# STM32F401CBU3 register map
File version: 1.0
STM32F401CBU3,STM32F401CBU6,STM32F401CBU7,STM32F401CBY6,STM32F401CCF6,STM32F401CCF7,STM32F401CCU6,STM32F401CCU7,STM32F401CCY6,STM32F401CCY7,STM32F401CDU6,STM32F401CDY6,STM32F401CEU6,STM32F401CEY6,STM32F401RBT6,STM32F401RCT6,STM32F401RCT7,STM32F401RDT6,STM32F401RDT7,STM32F401RET6,STM32F401RET7,STM32F401VBH3,STM32F401VBH6,STM32F401VBH7,STM32F401VBT3,STM32F401VBT6,STM32F401VBT7,STM32F401VCH6,STM32F401VCH7,STM32F401VCT6,STM32F401VCT7,STM32F401VDH6,STM32F401VDT6,STM32F401VEH6,STM32F401VEH7,STM32F401VET6,STM32F401VET7
Registers are 32-bit, access not given, reset 0x0 unless marked. A register's access mark holds for its fields unless they carry their own. Offsets are from the block's base; lines under a group give offsets from that group; [hi:lo] are bit positions; {n}, {i} and the like mark numbered series; 'fields as' and 'values as' point back to an identical list; <NAME> marks a mode.

## Memory map
0x40000000 TIM2
0x40000400 TIM3
0x40000800 TIM4
0x40000C00 TIM5
0x40002800 BKP
0x40002800 RTC
0x40002C00 WWDG
0x40003000 IWDG
0x40003800 SPI2
0x40003C00 SPI3
0x40004400 USART2
0x40005400 I2C1
0x40005800 I2C2
0x40005C00 I2C3
0x40007000 PWR
0x40010000 TIM1
0x40011000 USART1
0x40011400 USART6
0x40012000 ADC1
0x40012C00 SDIO
0x40013000 SPI1
0x40013400 SPI4
0x40013800 SYSCFG
0x40013C00 EXTI
0x40014000 TIM9
0x40014400 TIM10
0x40014800 TIM11
0x40020000 GPIOA
0x40020400 GPIOB
0x40020800 GPIOC
0x40020C00 GPIOD
0x40021000 GPIOE
0x40021C00 GPIOH
0x40023000 CRC
0x40023800 RCC
0x40023C00 FLASH
0x40026000 DMA1
0x40026400 DMA2
0x50000000 USB_OTG_FS

## TIM2
Base 0x40000000
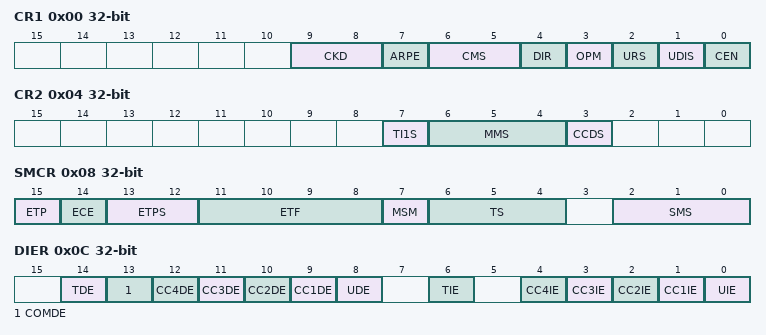
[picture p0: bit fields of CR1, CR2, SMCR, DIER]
0x00 CR1
  [9:8] CKD, [7] ARPE, [6:5] CMS, [4] DIR, [3] OPM, [2] URS, [1] UDIS, [0] CEN
0x04 CR2
  [7] TI1S, [6:4] MMS, [3] CCDS
0x08 SMCR
  [15] ETP, [14] ECE, [13:12] ETPS, [11:8] ETF, [7] MSM, [6:4] TS, [2:0] SMS
0x0C DIER
  [14] TDE, [13] COMDE, [n+8] CC{n}DE (n=1..4), [8] UDE, [6] TIE, [n] CC{n}IE (n=1..4), [0] UIE
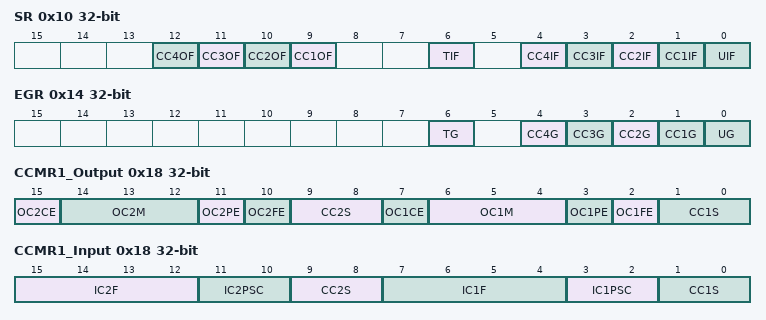
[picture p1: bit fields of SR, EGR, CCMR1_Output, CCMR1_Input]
0x10 SR
  [n+8] CC{n}OF (n=1..4), [6] TIF, [n] CC{n}IF (n=1..4), [0] UIF
0x14 EGR
  [6] TG, [n] CC{n}G (n=1..4), [0] UG
0x18 CCMR1_Output
  [15] OC2CE, [14:12] OC2M, [11] OC2PE, [10] OC2FE, [9:8] CC2S, [7] OC1CE, [6:4] OC1M, [3] OC1PE, [2] OC1FE, [1:0] CC1S
0x18 CCMR1_Input
  [15:12] IC2F, [11:10] IC2PSC, [9:8] CC2S, [7:4] IC1F, [3:2] IC1PSC, [1:0] CC1S
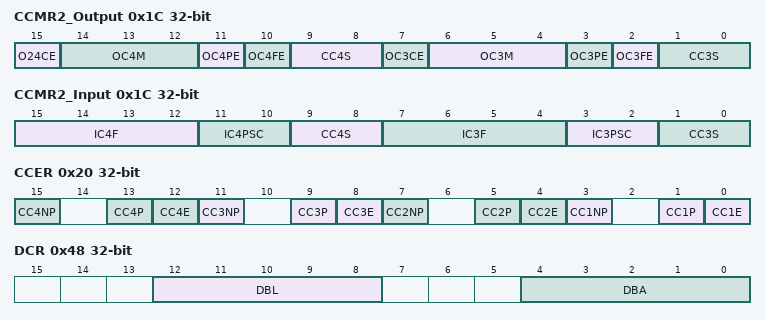
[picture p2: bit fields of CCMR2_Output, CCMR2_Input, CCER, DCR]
0x1C CCMR2_Output
  [15] O24CE, [14:12] OC4M, [11] OC4PE, [10] OC4FE, [9:8] CC4S, [7] OC3CE, [6:4] OC3M, [3] OC3PE, [2] OC3FE, [1:0] CC3S
0x1C CCMR2_Input
  [15:12] IC4F, [11:10] IC4PSC, [9:8] CC4S, [7:4] IC3F, [3:2] IC3PSC, [1:0] CC3S
0x20 CCER
  [4n-1] CC{n}NP (n=1..4), [4n-3] CC{n}P (n=1..4), [4n-4] CC{n}E (n=1..4)
0x24 CNT
0x28 PSC
  [15:0] PSC
0x2C ARR
{0x30+4i} CCR{i} (i=1..4)
0x48 DCR
  [12:8] DBL, [4:0] DBA
0x4C DMAR
  [15:0] DMAB
0x50 OR
  [11:10] ITR1_RMP

## TIM3
Base 0x40000400
Registers as TIM2, without OR.

## TIM4
Base 0x40000800
Registers as TIM2, without OR.

## TIM5
Base 0x40000C00
Registers as TIM2; these are added or differ:
0x50 OR
  [7:6] IT4_RMP

## BKP
Base 0x40002800
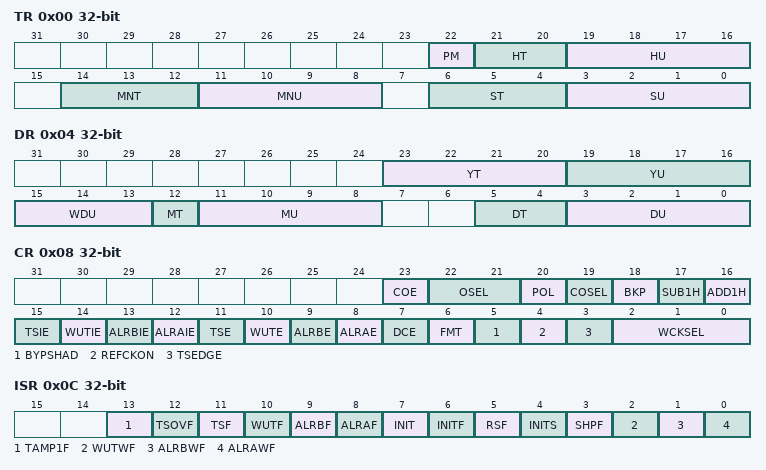
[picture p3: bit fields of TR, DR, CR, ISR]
0x00 TR
  [22] PM, [21:20] HT, [19:16] HU, [14:12] MNT, [11:8] MNU, [6:4] ST, [3:0] SU
0x04 DR
  [23:20] YT, [19:16] YU, [15:13] WDU, [12] MT, [11:8] MU, [5:4] DT, [3:0] DU
0x08 CR
  [23] COE, [22:21] OSEL, [20] POL, [19] COSEL, [18] BKP, [17] SUB1H, [16] ADD1H, [15] TSIE, [14] WUTIE, [13] ALRBIE, [12] ALRAIE, [11] TSE, [10] WUTE, [9] ALRBE, [8] ALRAE, [7] DCE, [6] FMT, [5] BYPSHAD, [4] REFCKON, [3] TSEDGE, [2:0] WCKSEL
0x0C ISR
  [13] TAMP1F, [12] TSOVF, [11] TSF, [10] WUTF, [9] ALRBF, [8] ALRAF, [7] INIT, [6] INITF, [5] RSF, [4] INITS, [3] SHPF, [2] WUTWF, [1] ALRBWF, [0] ALRAWF
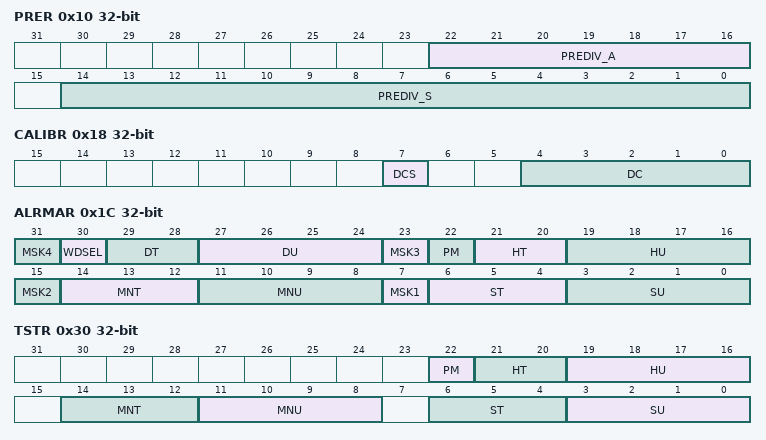
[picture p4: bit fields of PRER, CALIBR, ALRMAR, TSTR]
0x10 PRER
  [22:16] PREDIV_A, [14:0] PREDIV_S
0x14 WUTR
  [15:0] WUT
0x18 CALIBR
  [7] DCS, [4:0] DC
0x1C ALRMAR
  [8n-1] MSK{n} (n=1..4), [30] WDSEL, [29:28] DT, [27:24] DU, [22] PM, [21:20] HT, [19:16] HU, [14:12] MNT, [11:8] MNU, [6:4] ST, [3:0] SU
0x20 ALRMBR
  [31] MSK4, [30] WDSEL, [29:28] DT, [27:24] DU, [23] MSK3, [22] PM, [21:20] HT, [19:16] HU, [14:12] MNT, [11:8] MNU, [15:7] MSK2, [6:4] ST, [3:0] SU
0x24 WPR
  [7:0] KEY
0x28 SSR
  [15:0] SS
0x30 TSTR
  fields as TR
0x38 TSSSR
  [15:0] SS
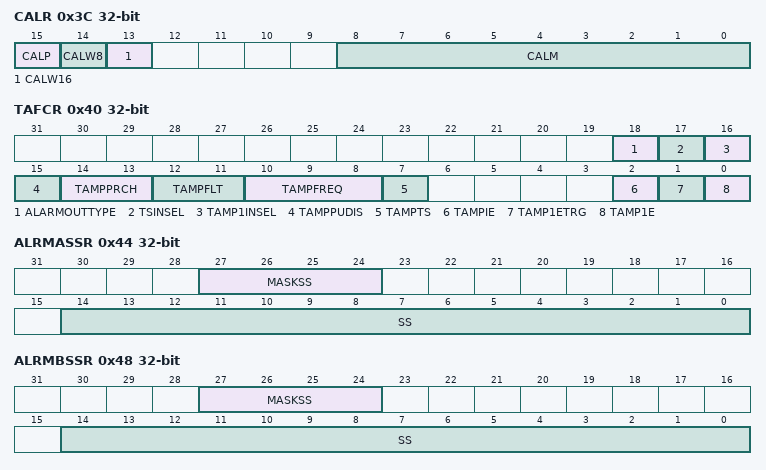
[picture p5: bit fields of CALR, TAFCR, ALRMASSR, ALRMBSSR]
0x3C CALR
  [15] CALP, [14] CALW8, [13] CALW16, [8:0] CALM
0x40 TAFCR
  [18] ALARMOUTTYPE, [17] TSINSEL, [16] TAMP1INSEL, [15] TAMPPUDIS, [14:13] TAMPPRCH, [12:11] TAMPFLT, [10:8] TAMPFREQ, [7] TAMPTS, [2] TAMPIE, [1] TAMP1ETRG, [0] TAMP1E
0x44 ALRMASSR
  [27:24] MASKSS, [14:0] SS
0x48 ALRMBSSR
  [27:24] MASKSS, [14:0] SS
{0x50+4i} BKP{i}R (i=0..19)
  [31:0] BKP

## RTC
Base 0x40002800
Registers as BKP; these are added or differ:
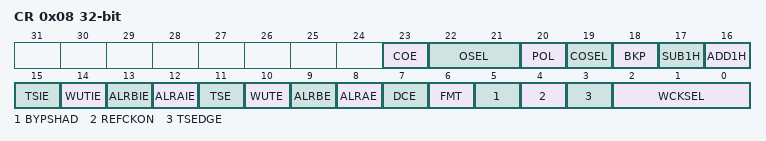
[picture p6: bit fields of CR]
0x08 CR
  fields as BKP.CR
{0x50+4i} BKP{i}R (i=0..19)
  [31:0] BKP
